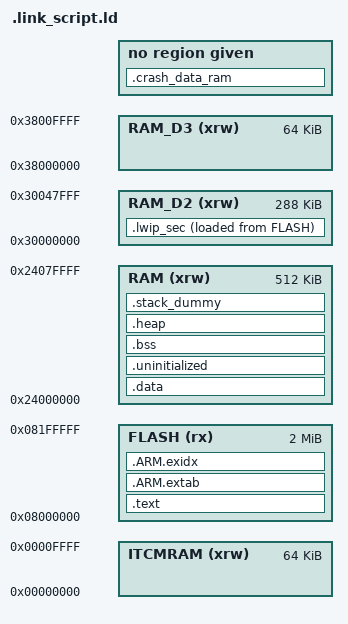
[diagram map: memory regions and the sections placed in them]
#define __STDC__ 1
#define __STDC_VERSION__ 201710L
#define __STDC_UTF_16__ 1
#define __STDC_UTF_32__ 1
#define __STDC_HOSTED__ 1
#define __GNUC__ 11
#define __GNUC_MINOR__ 2
#define __GNUC_PATCHLEVEL__ 1
#define __VERSION__ "11.2.1 20220111"
#define __ATOMIC_RELAXED 0
#define __ATOMIC_SEQ_CST 5
#define __ATOMIC_ACQUIRE 2
#define __ATOMIC_RELEASE 3
#define __ATOMIC_ACQ_REL 4
#define __ATOMIC_CONSUME 1
#define __OPTIMIZE_SIZE__ 1
#define __OPTIMIZE__ 1
#define __FINITE_MATH_ONLY__ 0
#define __SIZEOF_INT__ 4
#define __SIZEOF_LONG__ 4
#define __SIZEOF_LONG_LONG__ 8
#define __SIZEOF_SHORT__ 2
#define __SIZEOF_FLOAT__ 4
#define __SIZEOF_DOUBLE__ 8
#define __SIZEOF_LONG_DOUBLE__ 8
#define __SIZEOF_SIZE_T__ 4
#define __CHAR_BIT__ 8
#define __BIGGEST_ALIGNMENT__ 8
#define __ORDER_LITTLE_ENDIAN__ 1234
#define __ORDER_BIG_ENDIAN__ 4321
#define __ORDER_PDP_ENDIAN__ 3412
#define __BYTE_ORDER__ __ORDER_LITTLE_ENDIAN__
#define __FLOAT_WORD_ORDER__ __ORDER_LITTLE_ENDIAN__
#define __SIZEOF_POINTER__ 4
#define __GNUC_EXECUTION_CHARSET_NAME "UTF-8"
#define __GNUC_WIDE_EXECUTION_CHARSET_NAME "UTF-32LE"
#define __SIZE_TYPE__ unsigned int
#define __PTRDIFF_TYPE__ int
#define __WCHAR_TYPE__ unsigned int
#define __WINT_TYPE__ unsigned int
#define __INTMAX_TYPE__ long long int
#define __UINTMAX_TYPE__ long long unsigned int
#define __CHAR16_TYPE__ short unsigned int
#define __CHAR32_TYPE__ long unsigned int
#define __SIG_ATOMIC_TYPE__ int
#define __INT8_TYPE__ signed char
#define __INT16_TYPE__ short int
#define __INT32_TYPE__ long int
#define __INT64_TYPE__ long long int
#define __UINT8_TYPE__ unsigned char
#define __UINT16_TYPE__ short unsigned int
#define __UINT32_TYPE__ long unsigned int
#define __UINT64_TYPE__ long long unsigned int
#define __INT_LEAST8_TYPE__ signed char
#define __INT_LEAST16_TYPE__ short int
#define __INT_LEAST32_TYPE__ long int
#define __INT_LEAST64_TYPE__ long long int
#define __UINT_LEAST8_TYPE__ unsigned char
#define __UINT_LEAST16_TYPE__ short unsigned int
#define __UINT_LEAST32_TYPE__ long unsigned int
#define __UINT_LEAST64_TYPE__ long long unsigned int
#define __INT_FAST8_TYPE__ int
#define __INT_FAST16_TYPE__ int
#define __INT_FAST32_TYPE__ int
#define __INT_FAST64_TYPE__ long long int
#define __UINT_FAST8_TYPE__ unsigned int
#define __UINT_FAST16_TYPE__ unsigned int
#define __UINT_FAST32_TYPE__ unsigned int
#define __UINT_FAST64_TYPE__ long long unsigned int
#define __INTPTR_TYPE__ int
#define __UINTPTR_TYPE__ unsigned int
#define __GXX_ABI_VERSION 1016
#define __SCHAR_MAX__ 0x7f
#define __SHRT_MAX__ 0x7fff
#define __INT_MAX__ 0x7fffffff
#define __LONG_MAX__ 0x7fffffffL
#define __LONG_LONG_MAX__ 0x7fffffffffffffffLL
#define __WCHAR_MAX__ 0xffffffffU
#define __WCHAR_MIN__ 0U
#define __WINT_MAX__ 0xffffffffU
#define __WINT_MIN__ 0U
#define __PTRDIFF_MAX__ 0x7fffffff
#define __SIZE_MAX__ 0xffffffffU
#define __SCHAR_WIDTH__ 8
#define __SHRT_WIDTH__ 16
#define __INT_WIDTH__ 32
#define __LONG_WIDTH__ 32
#define __LONG_LONG_WIDTH__ 64
#define __WCHAR_WIDTH__ 32
#define __WINT_WIDTH__ 32
#define __PTRDIFF_WIDTH__ 32
#define __SIZE_WIDTH__ 32
#define __INTMAX_MAX__ 0x7fffffffffffffffLL
#define __INTMAX_C(c) c ## LL
#define __UINTMAX_MAX__ 0xffffffffffffffffULL
#define __UINTMAX_C(c) c ## ULL
#define __INTMAX_WIDTH__ 64
#define __SIG_ATOMIC_MAX__ 0x7fffffff
#define __SIG_ATOMIC_MIN__ (-__SIG_ATOMIC_MAX__ - 1)
#define __SIG_ATOMIC_WIDTH__ 32
#define __INT8_MAX__ 0x7f
#define __INT16_MAX__ 0x7fff
#define __INT32_MAX__ 0x7fffffffL
#define __INT64_MAX__ 0x7fffffffffffffffLL
#define __UINT8_MAX__ 0xff
#define __UINT16_MAX__ 0xffff
#define __UINT32_MAX__ 0xffffffffUL
#define __UINT64_MAX__ 0xffffffffffffffffULL
#define __INT_LEAST8_MAX__ 0x7f
#define __INT8_C(c) c
#define __INT_LEAST8_WIDTH__ 8
#define __INT_LEAST16_MAX__ 0x7fff
#define __INT16_C(c) c
#define __INT_LEAST16_WIDTH__ 16
#define __INT_LEAST32_MAX__ 0x7fffffffL
#define __INT32_C(c) c ## L
#define __INT_LEAST32_WIDTH__ 32
#define __INT_LEAST64_MAX__ 0x7fffffffffffffffLL
#define __INT64_C(c) c ## LL
#define __INT_LEAST64_WIDTH__ 64
#define __UINT_LEAST8_MAX__ 0xff
#define __UINT8_C(c) c
#define __UINT_LEAST16_MAX__ 0xffff
#define __UINT16_C(c) c
#define __UINT_LEAST32_MAX__ 0xffffffffUL
#define __UINT32_C(c) c ## UL
#define __UINT_LEAST64_MAX__ 0xffffffffffffffffULL
#define __UINT64_C(c) c ## ULL
#define __INT_FAST8_MAX__ 0x7fffffff
#define __INT_FAST8_WIDTH__ 32
#define __INT_FAST16_MAX__ 0x7fffffff
#define __INT_FAST16_WIDTH__ 32
#define __INT_FAST32_MAX__ 0x7fffffff
#define __INT_FAST32_WIDTH__ 32
#define __INT_FAST64_MAX__ 0x7fffffffffffffffLL
#define __INT_FAST64_WIDTH__ 64
#define __UINT_FAST8_MAX__ 0xffffffffU
#define __UINT_FAST16_MAX__ 0xffffffffU
#define __UINT_FAST32_MAX__ 0xffffffffU
#define __UINT_FAST64_MAX__ 0xffffffffffffffffULL
#define __INTPTR_MAX__ 0x7fffffff
#define __INTPTR_WIDTH__ 32
#define __UINTPTR_MAX__ 0xffffffffU
#define __GCC_IEC_559 2
#define __GCC_IEC_559_COMPLEX 2
#define __FLT_EVAL_METHOD__ 0
#define __FLT_EVAL_METHOD_TS_18661_3__ 0
#define __DEC_EVAL_METHOD__ 2
#define __FLT_RADIX__ 2
#define __FLT_MANT_DIG__ 24
#define __FLT_DIG__ 6
#define __FLT_MIN_EXP__ (-125)
#define __FLT_MIN_10_EXP__ (-37)
#define __FLT_MAX_EXP__ 128
#define __FLT_MAX_10_EXP__ 38
#define __FLT_DECIMAL_DIG__ 9
#define __FLT_MAX__ 3.4028234663852886e+38F
#define __FLT_NORM_MAX__ 3.4028234663852886e+38F
#define __FLT_MIN__ 1.1754943508222875e-38F
#define __FLT_EPSILON__ 1.1920928955078125e-7F
#define __FLT_DENORM_MIN__ 1.4012984643248171e-45F
#define __FLT_HAS_DENORM__ 1
#define __FLT_HAS_INFINITY__ 1
#define __FLT_HAS_QUIET_NAN__ 1
#define __FP_FAST_FMAF 1
#define __FLT_IS_IEC_60559__ 2
#define __DBL_MANT_DIG__ 53
#define __DBL_DIG__ 15
#define __DBL_MIN_EXP__ (-1021)
#define __DBL_MIN_10_EXP__ (-307)
#define __DBL_MAX_EXP__ 1024
#define __DBL_MAX_10_EXP__ 308
#define __DBL_DECIMAL_DIG__ 17
#define __DBL_MAX__ ((double)1.7976931348623157e+308L)
#define __DBL_NORM_MAX__ ((double)1.7976931348623157e+308L)
#define __DBL_MIN__ ((double)2.2250738585072014e-308L)
#define __DBL_EPSILON__ ((double)2.2204460492503131e-16L)
#define __DBL_DENORM_MIN__ ((double)4.9406564584124654e-324L)
#define __DBL_HAS_DENORM__ 1
#define __DBL_HAS_INFINITY__ 1
#define __DBL_HAS_QUIET_NAN__ 1
#define __FP_FAST_FMA 1
#define __DBL_IS_IEC_60559__ 2
#define __LDBL_MANT_DIG__ 53
#define __LDBL_DIG__ 15
#define __LDBL_MIN_EXP__ (-1021)
#define __LDBL_MIN_10_EXP__ (-307)
#define __LDBL_MAX_EXP__ 1024
#define __LDBL_MAX_10_EXP__ 308
#define __DECIMAL_DIG__ 17
#define __LDBL_DECIMAL_DIG__ 17
#define __LDBL_MAX__ 1.7976931348623157e+308L
#define __LDBL_NORM_MAX__ 1.7976931348623157e+308L
#define __LDBL_MIN__ 2.2250738585072014e-308L
#define __LDBL_EPSILON__ 2.2204460492503131e-16L
#define __LDBL_DENORM_MIN__ 4.9406564584124654e-324L
#define __LDBL_HAS_DENORM__ 1
#define __LDBL_HAS_INFINITY__ 1
#define __LDBL_HAS_QUIET_NAN__ 1
#define __FP_FAST_FMAL 1
#define __LDBL_IS_IEC_60559__ 2
#define __FLT32_MANT_DIG__ 24
#define __FLT32_DIG__ 6
#define __FLT32_MIN_EXP__ (-125)
#define __FLT32_MIN_10_EXP__ (-37)
#define __FLT32_MAX_EXP__ 128
#define __FLT32_MAX_10_EXP__ 38
#define __FLT32_DECIMAL_DIG__ 9
#define __FLT32_MAX__ 3.4028234663852886e+38F32
#define __FLT32_NORM_MAX__ 3.4028234663852886e+38F32
#define __FLT32_MIN__ 1.1754943508222875e-38F32
#define __FLT32_EPSILON__ 1.1920928955078125e-7F32
#define __FLT32_DENORM_MIN__ 1.4012984643248171e-45F32
#define __FLT32_HAS_DENORM__ 1
#define __FLT32_HAS_INFINITY__ 1
#define __FLT32_HAS_QUIET_NAN__ 1
#define __FP_FAST_FMAF32 1
#define __FLT32_IS_IEC_60559__ 2
#define __FLT64_MANT_DIG__ 53
#define __FLT64_DIG__ 15
#define __FLT64_MIN_EXP__ (-1021)
#define __FLT64_MIN_10_EXP__ (-307)
#define __FLT64_MAX_EXP__ 1024
#define __FLT64_MAX_10_EXP__ 308
#define __FLT64_DECIMAL_DIG__ 17
#define __FLT64_MAX__ 1.7976931348623157e+308F64
#define __FLT64_NORM_MAX__ 1.7976931348623157e+308F64
#define __FLT64_MIN__ 2.2250738585072014e-308F64
#define __FLT64_EPSILON__ 2.2204460492503131e-16F64
#define __FLT64_DENORM_MIN__ 4.9406564584124654e-324F64
#define __FLT64_HAS_DENORM__ 1
#define __FLT64_HAS_INFINITY__ 1
#define __FLT64_HAS_QUIET_NAN__ 1
#define __FP_FAST_FMAF64 1
#define __FLT64_IS_IEC_60559__ 2
#define __FLT32X_MANT_DIG__ 53
#define __FLT32X_DIG__ 15
#define __FLT32X_MIN_EXP__ (-1021)
#define __FLT32X_MIN_10_EXP__ (-307)
#define __FLT32X_MAX_EXP__ 1024
#define __FLT32X_MAX_10_EXP__ 308
#define __FLT32X_DECIMAL_DIG__ 17
#define __FLT32X_MAX__ 1.7976931348623157e+308F32x
#define __FLT32X_NORM_MAX__ 1.7976931348623157e+308F32x
#define __FLT32X_MIN__ 2.2250738585072014e-308F32x
#define __FLT32X_EPSILON__ 2.2204460492503131e-16F32x
#define __FLT32X_DENORM_MIN__ 4.9406564584124654e-324F32x
#define __FLT32X_HAS_DENORM__ 1
#define __FLT32X_HAS_INFINITY__ 1
#define __FLT32X_HAS_QUIET_NAN__ 1
#define __FP_FAST_FMAF32x 1
#define __FLT32X_IS_IEC_60559__ 2
#define __SFRACT_FBIT__ 7
#define __SFRACT_IBIT__ 0
#define __SFRACT_MIN__ (-0.5HR-0.5HR)
#define __SFRACT_MAX__ 0X7FP-7HR
#define __SFRACT_EPSILON__ 0x1P-7HR
#define __USFRACT_FBIT__ 8
#define __USFRACT_IBIT__ 0
#define __USFRACT_MIN__ 0.0UHR
#define __USFRACT_MAX__ 0XFFP-8UHR
#define __USFRACT_EPSILON__ 0x1P-8UHR
#define __FRACT_FBIT__ 15
#define __FRACT_IBIT__ 0
#define __FRACT_MIN__ (-0.5R-0.5R)
#define __FRACT_MAX__ 0X7FFFP-15R
#define __FRACT_EPSILON__ 0x1P-15R
#define __UFRACT_FBIT__ 16
#define __UFRACT_IBIT__ 0
#define __UFRACT_MIN__ 0.0UR
#define __UFRACT_MAX__ 0XFFFFP-16UR
#define __UFRACT_EPSILON__ 0x1P-16UR
#define __LFRACT_FBIT__ 31
#define __LFRACT_IBIT__ 0
#define __LFRACT_MIN__ (-0.5LR-0.5LR)
#define __LFRACT_MAX__ 0X7FFFFFFFP-31LR
#define __LFRACT_EPSILON__ 0x1P-31LR
#define __ULFRACT_FBIT__ 32
#define __ULFRACT_IBIT__ 0
#define __ULFRACT_MIN__ 0.0ULR
#define __ULFRACT_MAX__ 0XFFFFFFFFP-32ULR
#define __ULFRACT_EPSILON__ 0x1P-32ULR
#define __LLFRACT_FBIT__ 63
#define __LLFRACT_IBIT__ 0
#define __LLFRACT_MIN__ (-0.5LLR-0.5LLR)
#define __LLFRACT_MAX__ 0X7FFFFFFFFFFFFFFFP-63LLR
#define __LLFRACT_EPSILON__ 0x1P-63LLR
#define __ULLFRACT_FBIT__ 64
#define __ULLFRACT_IBIT__ 0
#define __ULLFRACT_MIN__ 0.0ULLR
#define __ULLFRACT_MAX__ 0XFFFFFFFFFFFFFFFFP-64ULLR
#define __ULLFRACT_EPSILON__ 0x1P-64ULLR
#define __SACCUM_FBIT__ 7
#define __SACCUM_IBIT__ 8
#define __SACCUM_MIN__ (-0X1P7HK-0X1P7HK)
#define __SACCUM_MAX__ 0X7FFFP-7HK
#define __SACCUM_EPSILON__ 0x1P-7HK
#define __USACCUM_FBIT__ 8
#define __USACCUM_IBIT__ 8
#define __USACCUM_MIN__ 0.0UHK
#define __USACCUM_MAX__ 0XFFFFP-8UHK
#define __USACCUM_EPSILON__ 0x1P-8UHK
#define __ACCUM_FBIT__ 15
#define __ACCUM_IBIT__ 16
#define __ACCUM_MIN__ (-0X1P15K-0X1P15K)
#define __ACCUM_MAX__ 0X7FFFFFFFP-15K
#define __ACCUM_EPSILON__ 0x1P-15K
#define __UACCUM_FBIT__ 16
#define __UACCUM_IBIT__ 16
#define __UACCUM_MIN__ 0.0UK
#define __UACCUM_MAX__ 0XFFFFFFFFP-16UK
#define __UACCUM_EPSILON__ 0x1P-16UK
#define __LACCUM_FBIT__ 31
#define __LACCUM_IBIT__ 32
#define __LACCUM_MIN__ (-0X1P31LK-0X1P31LK)
#define __LACCUM_MAX__ 0X7FFFFFFFFFFFFFFFP-31LK
#define __LACCUM_EPSILON__ 0x1P-31LK
#define __ULACCUM_FBIT__ 32
#define __ULACCUM_IBIT__ 32
#define __ULACCUM_MIN__ 0.0ULK
#define __ULACCUM_MAX__ 0XFFFFFFFFFFFFFFFFP-32ULK
#define __ULACCUM_EPSILON__ 0x1P-32ULK
#define __LLACCUM_FBIT__ 31
#define __LLACCUM_IBIT__ 32
#define __LLACCUM_MIN__ (-0X1P31LLK-0X1P31LLK)
#define __LLACCUM_MAX__ 0X7FFFFFFFFFFFFFFFP-31LLK
#define __LLACCUM_EPSILON__ 0x1P-31LLK
#define __ULLACCUM_FBIT__ 32
#define __ULLACCUM_IBIT__ 32
#define __ULLACCUM_MIN__ 0.0ULLK
#define __ULLACCUM_MAX__ 0XFFFFFFFFFFFFFFFFP-32ULLK
#define __ULLACCUM_EPSILON__ 0x1P-32ULLK
#define __QQ_FBIT__ 7
#define __QQ_IBIT__ 0
#define __HQ_FBIT__ 15
#define __HQ_IBIT__ 0
#define __SQ_FBIT__ 31
#define __SQ_IBIT__ 0
#define __DQ_FBIT__ 63
#define __DQ_IBIT__ 0
#define __TQ_FBIT__ 127
#define __TQ_IBIT__ 0
#define __UQQ_FBIT__ 8
#define __UQQ_IBIT__ 0
#define __UHQ_FBIT__ 16
#define __UHQ_IBIT__ 0
#define __USQ_FBIT__ 32
#define __USQ_IBIT__ 0
#define __UDQ_FBIT__ 64
#define __UDQ_IBIT__ 0
#define __UTQ_FBIT__ 128
#define __UTQ_IBIT__ 0
#define __HA_FBIT__ 7
#define __HA_IBIT__ 8
#define __SA_FBIT__ 15
#define __SA_IBIT__ 16
#define __DA_FBIT__ 31
#define __DA_IBIT__ 32
#define __TA_FBIT__ 63
#define __TA_IBIT__ 64
#define __UHA_FBIT__ 8
#define __UHA_IBIT__ 8
#define __USA_FBIT__ 16
#define __USA_IBIT__ 16
#define __UDA_FBIT__ 32
#define __UDA_IBIT__ 32
#define __UTA_FBIT__ 64
#define __UTA_IBIT__ 64
#define __REGISTER_PREFIX__ 
#define __USER_LABEL_PREFIX__ 
#define __GNUC_STDC_INLINE__ 1
#define __CHAR_UNSIGNED__ 1
#define __GCC_HAVE_SYNC_COMPARE_AND_SWAP_1 1
#define __GCC_HAVE_SYNC_COMPARE_AND_SWAP_2 1
#define __GCC_HAVE_SYNC_COMPARE_AND_SWAP_4 1
#define __GCC_ATOMIC_BOOL_LOCK_FREE 2
#define __GCC_ATOMIC_CHAR_LOCK_FREE 2
#define __GCC_ATOMIC_CHAR16_T_LOCK_FREE 2
#define __GCC_ATOMIC_CHAR32_T_LOCK_FREE 2
#define __GCC_ATOMIC_WCHAR_T_LOCK_FREE 2
#define __GCC_ATOMIC_SHORT_LOCK_FREE 2
#define __GCC_ATOMIC_INT_LOCK_FREE 2
#define __GCC_ATOMIC_LONG_LOCK_FREE 2
#define __GCC_ATOMIC_LLONG_LOCK_FREE 1
#define __GCC_ATOMIC_TEST_AND_SET_TRUEVAL 1
#define __GCC_ATOMIC_POINTER_LOCK_FREE 2
#define __HAVE_SPECULATION_SAFE_VALUE 1
#define __GCC_HAVE_DWARF2_CFI_ASM 1
#define __PRAGMA_REDEFINE_EXTNAME 1
#define __SIZEOF_WCHAR_T__ 4
#define __SIZEOF_WINT_T__ 4
#define __SIZEOF_PTRDIFF_T__ 4
#define __ARM_FEATURE_DSP 1
#define __ARM_FEATURE_QBIT 1
#define __ARM_FEATURE_SAT 1
#undef __ARM_FEATURE_CRYPTO
#define __ARM_FEATURE_UNALIGNED 1
#undef __ARM_FEATURE_QRDMX
#undef __ARM_FEATURE_CRC32
#undef __ARM_FEATURE_DOTPROD
#undef __ARM_FEATURE_COMPLEX
#define __ARM_32BIT_STATE 1
#undef __ARM_FEATURE_MVE
#undef __ARM_FEATURE_CMSE
#undef __ARM_FEATURE_LDREX
#define __ARM_FEATURE_LDREX 7
#define __ARM_FEATURE_CLZ 1
#undef __ARM_FEATURE_NUMERIC_MAXMIN
#define __ARM_FEATURE_SIMD32 1
#define __ARM_SIZEOF_MINIMAL_ENUM 1
#define __ARM_SIZEOF_WCHAR_T 4
#undef __ARM_ARCH_PROFILE
#define __ARM_ARCH_PROFILE 77
#define __arm__ 1
#undef __ARM_ARCH
#define __ARM_ARCH 7
#define __APCS_32__ 1
#define __GCC_ASM_FLAG_OUTPUTS__ 1
#define __thumb__ 1
#define __thumb2__ 1
#define __THUMBEL__ 1
#undef __ARM_ARCH_ISA_THUMB
#define __ARM_ARCH_ISA_THUMB 2
#define __ARMEL__ 1
#define __VFP_FP__ 1
#undef __ARM_FP
#define __ARM_FP 14
#undef __ARM_FP16_FORMAT_IEEE
#undef __ARM_FP16_FORMAT_ALTERNATIVE
#undef __ARM_FP16_ARGS
#undef __ARM_FEATURE_FP16_SCALAR_ARITHMETIC
#undef __ARM_FEATURE_FP16_VECTOR_ARITHMETIC
#undef __ARM_FEATURE_FP16_FML
#define __ARM_FEATURE_FMA 1
#undef __ARM_NEON__
#undef __ARM_NEON
#undef __ARM_NEON_FP
#define __THUMB_INTERWORK__ 1
#define __ARM_ARCH_7EM__ 1
#define __ARM_PCS 1
#define __ARM_EABI__ 1
#undef __FDPIC__
#define __ARM_ARCH_EXT_IDIV__ 1
#define __ARM_FEATURE_IDIV 1
#define __ARM_ASM_SYNTAX_UNIFIED__ 1
#undef __ARM_FEATURE_COPROC
#define __ARM_FEATURE_COPROC 15
#undef __ARM_FEATURE_CDE
#undef __ARM_FEATURE_CDE_COPROC
#undef __ARM_FEATURE_MATMUL_INT8
#undef __ARM_FEATURE_BF16_SCALAR_ARITHMETIC
#undef __ARM_FEATURE_BF16_VECTOR_ARITHMETIC
#undef __ARM_BF16_FORMAT_ALTERNATIVE
#define __GXX_TYPEINFO_EQUALITY_INLINE 0
#define __ELF__ 1
#define __USES_INITFINI__ 1
#define MBED_TRAP_ERRORS_ENABLED 1
#define BOOST_NO_PLATFORM_CONFIG 1
#define RT_ARM_MBED 1
#define RT_DEVS 1
#define MBED_MINIMAL_PRINTF 1
#define MBED_ROM_START 0x8000000
#define MBED_ROM_SIZE 0x200000
#define MBED_RAM_START 0x20000000
#define MBED_RAM_SIZE 0x20000
#define MBED_RAM1_START 0x24000000
#define MBED_RAM1_SIZE 0x80000
#define MBED_BOOT_STACK_SIZE 1024
#define XIP_ENABLE 0
#define TARGET_NUCLEO_H743ZI2 1
#define __CMSIS_RTOS 1
#define COMPONENT_FLASHIAP 1
#define MBED_TICKLESS 1
#define DEVICE_CAN 1
#define TARGET_LIKE_CORTEX_M7 1
#define DEVICE_PORTIN 1
#define TOOLCHAIN_GCC_ARM 1
#define __FPU_PRESENT 1
#define USE_FULL_LL_DRIVER 1
#define DEVICE_PORTOUT 1
#define TARGET_NAME NUCLEO_H743ZI2
#define DEVICE_I2C_ASYNCH 1
#define TARGET_STM32H743xI 1
#define TARGET_RTOS_M4_M7 1
#define DEVICE_SPI_ASYNCH 1
#define TARGET_FF_ARDUINO_UNO 1
#define __MBED_CMSIS_RTOS_CM 1
#define DEVICE_TRNG 1
#define MBED_BUILD_TIMESTAMP 1658340624.951455
#define DEVICE_RESET_REASON 1
#define DEVICE_SLEEP 1
#define DEVICE_PWMOUT 1
#define DEVICE_LPTICKER 1
#define TARGET_CORTEX 1
#define DEVICE_SERIAL 1
#define DEVICE_FLASH 1
#define STM32H743xx 1
#define TARGET_MCU_STM32H7 1
#define DEVICE_USBDEVICE 1
#define TARGET_LIKE_MBED 1
#define DEVICE_ANALOGOUT 1
#define TARGET_MCU_STM32 1
#define __MBED__ 1
#define DEVICE_INTERRUPTIN 1
#define DEVICE_MPU 1
#define DEVICE_SPISLAVE 1
#define TARGET_CORTEX_M 1
#define TARGET_M7 1
#define TOOLCHAIN_GCC 1
#define USE_HAL_DRIVER 1
#define DEVICE_EMAC 1
#define DEVICE_SERIAL_FC 1
#define TARGET_MCU_STM32H743xI 1
#define DEVICE_PORTINOUT 1
#define TARGET_STM 1
#define DEVICE_I2CSLAVE 1
#define DEVICE_CRC 1
#define DEVICE_USTICKER 1
#define ARM_MATH_CM7 1
#define EXTRA_IDLE_STACK_REQUIRED 1
#define DEVICE_WATCHDOG 1
#define DEVICE_RTC 1
#define DEVICE_STDIO_MESSAGES 1
#define __CORTEX_M7 1
#define DEVICE_ANALOGIN 1
#define TARGET_STM32H7 1
#define TARGET_RELEASE 1
#define TRANSACTION_QUEUE_SIZE_SPI 2
#define DEVICE_SPI 1
#define DEVICE_I2C 1
#define __MBED_CONFIG_DATA__ 
#define CLOCK_SOURCE USE_PLL_HSE_EXTC|USE_PLL_HSI
#define HSE_VALUE 8000000
#define LPTICKER_DELAY_TICKS 0
#define MBED_CONF_ALT1250_PPP_BAUDRATE 115200
#define MBED_CONF_ALT1250_PPP_PROVIDE_DEFAULT 0
#define MBED_CONF_ATMEL_RF_ASSUME_SPACED_SPI 1
#define MBED_CONF_ATMEL_RF_FULL_SPI_SPEED 7500000
#define MBED_CONF_ATMEL_RF_FULL_SPI_SPEED_BYTE_SPACING 250
#define MBED_CONF_ATMEL_RF_IRQ_THREAD_STACK_SIZE 1024
#define MBED_CONF_ATMEL_RF_LOW_SPI_SPEED 3750000
#define MBED_CONF_ATMEL_RF_PROVIDE_DEFAULT 0
#define MBED_CONF_ATMEL_RF_USE_SPI_SPACING_API 0
#define MBED_CONF_CELLULAR_AT_HANDLER_BUFFER_SIZE 32
#define MBED_CONF_CELLULAR_CONTROL_PLANE_OPT 0
#define MBED_CONF_CELLULAR_DEBUG_AT 0
#define MBED_CONF_CELLULAR_MAX_CP_DATA_RECV_LEN 1358
#define MBED_CONF_CELLULAR_PRESENT 1
#define MBED_CONF_CELLULAR_RANDOM_MAX_START_DELAY 0
#define MBED_CONF_CELLULAR_USE_APN_LOOKUP 0
#define MBED_CONF_CELLULAR_USE_SMS 0
#define MBED_CONF_DRIVERS_OSPI_CSN OSPI_FLASH1_CSN
#define MBED_CONF_DRIVERS_OSPI_DQS OSPI_FLASH1_DQS
#define MBED_CONF_DRIVERS_OSPI_IO0 OSPI_FLASH1_IO0
#define MBED_CONF_DRIVERS_OSPI_IO1 OSPI_FLASH1_IO1
#define MBED_CONF_DRIVERS_OSPI_IO2 OSPI_FLASH1_IO2
#define MBED_CONF_DRIVERS_OSPI_IO3 OSPI_FLASH1_IO3
#define MBED_CONF_DRIVERS_OSPI_IO4 OSPI_FLASH1_IO4
#define MBED_CONF_DRIVERS_OSPI_IO5 OSPI_FLASH1_IO5
#define MBED_CONF_DRIVERS_OSPI_IO6 OSPI_FLASH1_IO6
#define MBED_CONF_DRIVERS_OSPI_IO7 OSPI_FLASH1_IO7
#define MBED_CONF_DRIVERS_OSPI_SCK OSPI_FLASH1_SCK
#define MBED_CONF_DRIVERS_QSPI_CSN QSPI_FLASH1_CSN
#define MBED_CONF_DRIVERS_QSPI_IO0 QSPI_FLASH1_IO0
#define MBED_CONF_DRIVERS_QSPI_IO1 QSPI_FLASH1_IO1
#define MBED_CONF_DRIVERS_QSPI_IO2 QSPI_FLASH1_IO2
#define MBED_CONF_DRIVERS_QSPI_IO3 QSPI_FLASH1_IO3
#define MBED_CONF_DRIVERS_QSPI_SCK QSPI_FLASH1_SCK
#define MBED_CONF_DRIVERS_UART_SERIAL_RXBUF_SIZE 256
#define MBED_CONF_DRIVERS_UART_SERIAL_TXBUF_SIZE 256
#define MBED_CONF_ESP8266_BUILT_IN_DNS 0
#define MBED_CONF_ESP8266_DEBUG 0
#define MBED_CONF_ESP8266_POWER_OFF_TIME_MS 3
#define MBED_CONF_ESP8266_POWER_ON_POLARITY 0
#define MBED_CONF_ESP8266_POWER_ON_TIME_MS 3
#define MBED_CONF_ESP8266_PROVIDE_DEFAULT 0
#define MBED_CONF_ESP8266_SERIAL_BAUDRATE 115200
#define MBED_CONF_ESP8266_SNTP_ENABLE 0
#define MBED_CONF_ESP8266_SNTP_SERVER0 ""
#define MBED_CONF_ESP8266_SNTP_SERVER1 ""
#define MBED_CONF_ESP8266_SNTP_SERVER2 ""
#define MBED_CONF_ESP8266_SNTP_TIMEZONE 0
#define MBED_CONF_ESP8266_SOCKET_BUFSIZE 8192
#define MBED_CONF_EVENTS_PRESENT 1
#define MBED_CONF_EVENTS_SHARED_DISPATCH_FROM_APPLICATION 0
#define MBED_CONF_EVENTS_SHARED_EVENTSIZE 768
#define MBED_CONF_EVENTS_SHARED_HIGHPRIO_EVENTSIZE 256
#define MBED_CONF_EVENTS_SHARED_HIGHPRIO_STACKSIZE 1024
#define MBED_CONF_EVENTS_SHARED_STACKSIZE 2048
#define MBED_CONF_EVENTS_USE_LOWPOWER_TIMER_TICKER 0
#define MBED_CONF_FAT_CHAN_FFS_DBG 0
#define MBED_CONF_FAT_CHAN_FF_CODE_PAGE 437
#define MBED_CONF_FAT_CHAN_FF_FS_EXFAT 0
#define MBED_CONF_FAT_CHAN_FF_FS_HEAPBUF 1
#define MBED_CONF_FAT_CHAN_FF_FS_LOCK 0
#define MBED_CONF_FAT_CHAN_FF_FS_MINIMIZE 0
#define MBED_CONF_FAT_CHAN_FF_FS_NOFSINFO 0
#define MBED_CONF_FAT_CHAN_FF_FS_NORTC 0
#define MBED_CONF_FAT_CHAN_FF_FS_READONLY 0
#define MBED_CONF_FAT_CHAN_FF_FS_REENTRANT 0
#define MBED_CONF_FAT_CHAN_FF_FS_RPATH 1
#define MBED_CONF_FAT_CHAN_FF_FS_TIMEOUT 1000
#define MBED_CONF_FAT_CHAN_FF_FS_TINY 1
#define MBED_CONF_FAT_CHAN_FF_LFN_BUF 255
#define MBED_CONF_FAT_CHAN_FF_LFN_UNICODE 0
#define MBED_CONF_FAT_CHAN_FF_MAX_LFN 255
#define MBED_CONF_FAT_CHAN_FF_MAX_SS 4096
#define MBED_CONF_FAT_CHAN_FF_MIN_SS 512
#define MBED_CONF_FAT_CHAN_FF_MULTI_PARTITION 0
#define MBED_CONF_FAT_CHAN_FF_NORTC_MDAY 1
#define MBED_CONF_FAT_CHAN_FF_NORTC_MON 1
#define MBED_CONF_FAT_CHAN_FF_NORTC_YEAR 2017
#define MBED_CONF_FAT_CHAN_FF_PRINT_FLOAT 0
#define MBED_CONF_FAT_CHAN_FF_PRINT_LLI 0
#define MBED_CONF_FAT_CHAN_FF_SFN_BUF 12
#define MBED_CONF_FAT_CHAN_FF_STRF_ENCODE 3
#define MBED_CONF_FAT_CHAN_FF_STR_VOLUME_ID 0
#define MBED_CONF_FAT_CHAN_FF_SYNC_T HANDLE
#define MBED_CONF_FAT_CHAN_FF_USE_CHMOD 0
#define MBED_CONF_FAT_CHAN_FF_USE_EXPAND 0
#define MBED_CONF_FAT_CHAN_FF_USE_FASTSEEK 0
#define MBED_CONF_FAT_CHAN_FF_USE_FIND 0
#define MBED_CONF_FAT_CHAN_FF_USE_FORWARD 0
#define MBED_CONF_FAT_CHAN_FF_USE_LABEL 0
#define MBED_CONF_FAT_CHAN_FF_USE_LFN 3
#define MBED_CONF_FAT_CHAN_FF_USE_MKFS 1
#define MBED_CONF_FAT_CHAN_FF_USE_STRFUNC 0
#define MBED_CONF_FAT_CHAN_FF_USE_TRIM 1
#define MBED_CONF_FAT_CHAN_FF_VOLUMES 4
#define MBED_CONF_FAT_CHAN_FF_VOLUME_STRS "RAM","NAND","CF","SD","SD2","USB","USB2","USB3"
#define MBED_CONF_FAT_CHAN_FLUSH_ON_NEW_CLUSTER 0
#define MBED_CONF_FAT_CHAN_FLUSH_ON_NEW_SECTOR 1
#define MBED_CONF_FILESYSTEM_PRESENT 1
#define MBED_CONF_FLASHIAP_BLOCK_DEVICE_BASE_ADDRESS 0xFFFFFFFF
#define MBED_CONF_FLASHIAP_BLOCK_DEVICE_SIZE 0
#define MBED_CONF_GEMALTO_CINTERION_BAUDRATE 115200
#define MBED_CONF_GEMALTO_CINTERION_PROVIDE_DEFAULT 0
#define MBED_CONF_GENERIC_AT3GPP_BAUDRATE 115200
#define MBED_CONF_GENERIC_AT3GPP_PROVIDE_DEFAULT 0
#define MBED_CONF_LORA_ADR_ON 1
#define MBED_CONF_LORA_APPLICATION_EUI {0x00, 0x00, 0x00, 0x00, 0x00, 0x00, 0x00, 0x00}
#define MBED_CONF_LORA_APPLICATION_KEY {0x00, 0x00, 0x00, 0x00, 0x00, 0x00, 0x00, 0x00, 0x00, 0x00, 0x00, 0x00, 0x00, 0x00, 0x00, 0x00}
#define MBED_CONF_LORA_APPSKEY {0x00, 0x00, 0x00, 0x00, 0x00, 0x00, 0x00, 0x00, 0x00, 0x00, 0x00, 0x00, 0x00, 0x00, 0x00, 0x00}
#define MBED_CONF_LORA_APP_PORT 15
#define MBED_CONF_LORA_AUTOMATIC_UPLINK_MESSAGE 1
#define MBED_CONF_LORA_DEVICE_ADDRESS 0x00000000
#define MBED_CONF_LORA_DEVICE_EUI {0x00, 0x00, 0x00, 0x00, 0x00, 0x00, 0x00, 0x00}
#define MBED_CONF_LORA_DOWNLINK_PREAMBLE_LENGTH 5
#define MBED_CONF_LORA_DUTY_CYCLE_ON 1
#define MBED_CONF_LORA_DUTY_CYCLE_ON_JOIN 1
#define MBED_CONF_LORA_FSB_MASK {0xFFFF, 0xFFFF, 0xFFFF, 0xFFFF, 0x00FF}
#define MBED_CONF_LORA_FSB_MASK_CHINA {0xFFFF, 0xFFFF, 0xFFFF, 0xFFFF, 0xFFFF, 0xFFFF}
#define MBED_CONF_LORA_LBT_ON 0
#define MBED_CONF_LORA_MAX_SYS_RX_ERROR 5
#define MBED_CONF_LORA_NB_TRIALS 12
#define MBED_CONF_LORA_NWKSKEY {0x00, 0x00, 0x00, 0x00, 0x00, 0x00, 0x00, 0x00, 0x00, 0x00, 0x00, 0x00, 0x00, 0x00, 0x00, 0x00}
#define MBED_CONF_LORA_OVER_THE_AIR_ACTIVATION 1
#define MBED_CONF_LORA_PHY EU868
#define MBED_CONF_LORA_PUBLIC_NETWORK 1
#define MBED_CONF_LORA_TX_MAX_SIZE 64
#define MBED_CONF_LORA_UPLINK_PREAMBLE_LENGTH 8
#define MBED_CONF_LORA_WAKEUP_TIME 5
#define MBED_CONF_LWIP_ADDR_TIMEOUT 5
#define MBED_CONF_LWIP_ADDR_TIMEOUT_MODE 1
#define MBED_CONF_LWIP_DEBUG_ENABLED 0
#define MBED_CONF_LWIP_DEFAULT_THREAD_STACKSIZE 512
#define MBED_CONF_LWIP_DHCP_TIMEOUT 60
#define MBED_CONF_LWIP_ENABLE_PPP_TRACE 0
#define MBED_CONF_LWIP_ETHERNET_ENABLED 1
#define MBED_CONF_LWIP_IPV4_ENABLED 1
#define MBED_CONF_LWIP_IPV6_ENABLED 0
#define MBED_CONF_LWIP_IP_VER_PREF 4
#define MBED_CONF_LWIP_L3IP_ENABLED 0
#define MBED_CONF_LWIP_MBOX_SIZE 8
#define MBED_CONF_LWIP_MEMP_NUM_TCPIP_MSG_INPKT 8
#define MBED_CONF_LWIP_MEMP_NUM_TCP_SEG 16
#define MBED_CONF_LWIP_MEM_SIZE 2310
#define MBED_CONF_LWIP_ND6_QUEUEING 0
#define MBED_CONF_LWIP_ND6_RDNSS_MAX_DNS_SERVERS 0
#define MBED_CONF_LWIP_NETBUF_RECVINFO_ENABLED 0
#define MBED_CONF_LWIP_NUM_NETBUF 8
#define MBED_CONF_LWIP_NUM_PBUF 8
#define MBED_CONF_LWIP_PBUF_POOL_SIZE 5
#define MBED_CONF_LWIP_PPP_ENABLED 0
#define MBED_CONF_LWIP_PPP_IPV4_ENABLED 0
#define MBED_CONF_LWIP_PPP_IPV6_ENABLED 0
#define MBED_CONF_LWIP_PPP_THREAD_STACKSIZE 768
#define MBED_CONF_LWIP_PRESENT 1
#define MBED_CONF_LWIP_RAW_SOCKET_ENABLED 0
#define MBED_CONF_LWIP_SOCKET_MAX 4
#define MBED_CONF_LWIP_TCPIP_THREAD_PRIORITY osPriorityNormal
#define MBED_CONF_LWIP_TCPIP_THREAD_STACKSIZE 1200
#define MBED_CONF_LWIP_TCP_CLOSE_TIMEOUT 1000
#define MBED_CONF_LWIP_TCP_ENABLED 1
#define MBED_CONF_LWIP_TCP_MAXRTX 6
#define MBED_CONF_LWIP_TCP_MSS 536
#define MBED_CONF_LWIP_TCP_SERVER_MAX 4
#define MBED_CONF_LWIP_TCP_SND_BUF (2 * TCP_MSS)
#define MBED_CONF_LWIP_TCP_SOCKET_MAX 4
#define MBED_CONF_LWIP_TCP_SYNMAXRTX 6
#define MBED_CONF_LWIP_TCP_WND (4 * TCP_MSS)
#define MBED_CONF_LWIP_UDP_SOCKET_MAX 4
#define MBED_CONF_LWIP_USE_MBED_TRACE 0
#define MBED_CONF_MBED_MESH_API_6LOWPAN_ND_CHANNEL 0
#define MBED_CONF_MBED_MESH_API_6LOWPAN_ND_CHANNEL_MASK 0x7fff800
#define MBED_CONF_MBED_MESH_API_6LOWPAN_ND_CHANNEL_PAGE 0
#define MBED_CONF_MBED_MESH_API_6LOWPAN_ND_DEVICE_TYPE NET_6LOWPAN_ROUTER
#define MBED_CONF_MBED_MESH_API_6LOWPAN_ND_PANID_FILTER 0xffff
#define MBED_CONF_MBED_MESH_API_6LOWPAN_ND_PSK_KEY {0xa0, 0xa1, 0xa2, 0xa3, 0xa4, 0xa5, 0xa6, 0xa7, 0xa8, 0xa9, 0xaa, 0xab, 0xac, 0xad, 0xae, 0xaf}
#define MBED_CONF_MBED_MESH_API_6LOWPAN_ND_PSK_KEY_ID 1
#define MBED_CONF_MBED_MESH_API_6LOWPAN_ND_SECURITY_MODE NONE
#define MBED_CONF_MBED_MESH_API_6LOWPAN_ND_SEC_LEVEL 5
#define MBED_CONF_MBED_MESH_API_HEAP_SIZE 32500
#define MBED_CONF_MBED_MESH_API_HEAP_STAT_INFO NULL
#define MBED_CONF_MBED_MESH_API_MAC_NEIGH_TABLE_SIZE 32
#define MBED_CONF_MBED_MESH_API_RADIUS_RETRY_COUNT 3
#define MBED_CONF_MBED_MESH_API_RADIUS_RETRY_IMAX 30
#define MBED_CONF_MBED_MESH_API_RADIUS_RETRY_IMIN 20
#define MBED_CONF_MBED_MESH_API_SYSTEM_TIME_UPDATE_FROM_NANOSTACK 1
#define MBED_CONF_MBED_MESH_API_THREAD_CONFIG_CHANNEL 22
#define MBED_CONF_MBED_MESH_API_THREAD_CONFIG_CHANNEL_MASK 0x7fff800
#define MBED_CONF_MBED_MESH_API_THREAD_CONFIG_CHANNEL_PAGE 0
#define MBED_CONF_MBED_MESH_API_THREAD_CONFIG_COMMISSIONING_DATASET_TIMESTAMP 0x10000
#define MBED_CONF_MBED_MESH_API_THREAD_CONFIG_EXTENDED_PANID {0xf1, 0xb5, 0xa1, 0xb2,0xc4, 0xd5, 0xa1, 0xbd }
#define MBED_CONF_MBED_MESH_API_THREAD_CONFIG_ML_PREFIX {0xfd, 0x0, 0x0d, 0xb8, 0x0, 0x0, 0x0, 0x0}
#define MBED_CONF_MBED_MESH_API_THREAD_CONFIG_NETWORK_NAME "Thread Network"
#define MBED_CONF_MBED_MESH_API_THREAD_CONFIG_PANID 0x0700
#define MBED_CONF_MBED_MESH_API_THREAD_CONFIG_PSKC {0xc8, 0xa6, 0x2e, 0xae, 0xf3, 0x68, 0xf3, 0x46, 0xa9, 0x9e, 0x57, 0x85, 0x98, 0x9d, 0x1c, 0xd0}
#define MBED_CONF_MBED_MESH_API_THREAD_DEVICE_TYPE MESH_DEVICE_TYPE_THREAD_ROUTER
#define MBED_CONF_MBED_MESH_API_THREAD_MASTER_KEY {0x10, 0x11, 0x22, 0x33, 0x44, 0x55, 0x66, 0x77, 0x88, 0x99, 0xaa, 0xbb, 0xcc, 0xdd, 0xee, 0xff}
#define MBED_CONF_MBED_MESH_API_THREAD_PSKD "ABCDEFGH"
#define MBED_CONF_MBED_MESH_API_THREAD_SECURITY_POLICY 255
#define MBED_CONF_MBED_MESH_API_THREAD_USE_STATIC_LINK_CONFIG 1
#define MBED_CONF_MBED_MESH_API_USE_MALLOC_FOR_HEAP 0
#define MBED_CONF_MBED_MESH_API_WISUN_BC_CHANNEL_FUNCTION 255
#define MBED_CONF_MBED_MESH_API_WISUN_BC_DWELL_INTERVAL 0
#define MBED_CONF_MBED_MESH_API_WISUN_BC_FIXED_CHANNEL 65535
#define MBED_CONF_MBED_MESH_API_WISUN_BC_INTERVAL 0
#define MBED_CONF_MBED_MESH_API_WISUN_CHANNEL_PLAN_ID 255
#define MBED_CONF_MBED_MESH_API_WISUN_DEVICE_TYPE MESH_DEVICE_TYPE_WISUN_ROUTER
#define MBED_CONF_MBED_MESH_API_WISUN_NETWORK_NAME "Wi-SUN Network"
#define MBED_CONF_MBED_MESH_API_WISUN_OPERATING_CLASS 255
#define MBED_CONF_MBED_MESH_API_WISUN_OPERATING_MODE 255
#define MBED_CONF_MBED_MESH_API_WISUN_PHY_MODE_ID 255
#define MBED_CONF_MBED_MESH_API_WISUN_REGULATORY_DOMAIN 3
#define MBED_CONF_MBED_MESH_API_WISUN_UC_CHANNEL_FUNCTION 255
#define MBED_CONF_MBED_MESH_API_WISUN_UC_DWELL_INTERVAL 255
#define MBED_CONF_MBED_MESH_API_WISUN_UC_FIXED_CHANNEL 65535
#define MBED_CONF_MCR20A_PROVIDE_DEFAULT 0
#define MBED_CONF_NANOSTACK_CONFIGURATION nanostack_full
#define MBED_CONF_NANOSTACK_HAL_CRITICAL_SECTION_USABLE_FROM_INTERRUPT 0
#define MBED_CONF_NANOSTACK_HAL_EVENT_LOOP_DISPATCH_FROM_APPLICATION 0
#define MBED_CONF_NANOSTACK_HAL_EVENT_LOOP_THREAD_STACK_SIZE 6144
#define MBED_CONF_NANOSTACK_HAL_EVENT_LOOP_USE_MBED_EVENTS 0
#define MBED_CONF_NANOSTACK_HAL_KVSTORE_PATH "/kv/"
#define MBED_CONF_NANOSTACK_HAL_USE_KVSTORE 0
#define MBED_CONF_NANOSTACK_LIBSERVICE_NSDYNMEM_TRACKER_ENABLED 0
#define MBED_CONF_NANOSTACK_LIBSERVICE_PRESENT 1
#define MBED_CONF_NSAPI_ADD_EVENT_LISTENER_RETURN_CHANGE 0
#define MBED_CONF_NSAPI_DEFAULT_MESH_TYPE THREAD
#define MBED_CONF_NSAPI_DEFAULT_STACK LWIP
#define MBED_CONF_NSAPI_DEFAULT_WIFI_SECURITY NONE
#define MBED_CONF_NSAPI_DNS_ADDRESSES_LIMIT 10
#define MBED_CONF_NSAPI_DNS_CACHE_SIZE 3
#define MBED_CONF_NSAPI_DNS_RESPONSE_WAIT_TIME 10000
#define MBED_CONF_NSAPI_DNS_RETRIES 1
#define MBED_CONF_NSAPI_DNS_TOTAL_ATTEMPTS 10
#define MBED_CONF_NSAPI_PRESENT 1
#define MBED_CONF_NSAPI_SOCKET_STATS_ENABLED 0
#define MBED_CONF_NSAPI_SOCKET_STATS_MAX_COUNT 10
#define MBED_CONF_PLATFORM_CALLBACK_COMPARABLE 1
#define MBED_CONF_PLATFORM_CALLBACK_NONTRIVIAL 0
#define MBED_CONF_PLATFORM_CRASH_CAPTURE_ENABLED 0
#define MBED_CONF_PLATFORM_CTHUNK_COUNT_MAX 8
#define MBED_CONF_PLATFORM_DEEPSLEEP_STATS_VERBOSE 0
#define MBED_CONF_PLATFORM_DEFAULT_SERIAL_BAUD_RATE 9600
#define MBED_CONF_PLATFORM_ERROR_ALL_THREADS_INFO 0
#define MBED_CONF_PLATFORM_ERROR_FILENAME_CAPTURE_ENABLED 0
#define MBED_CONF_PLATFORM_ERROR_HIST_ENABLED 0
#define MBED_CONF_PLATFORM_ERROR_HIST_SIZE 4
#define MBED_CONF_PLATFORM_ERROR_REBOOT_MAX 1
#define MBED_CONF_PLATFORM_FATAL_ERROR_AUTO_REBOOT_ENABLED 0
#define MBED_CONF_PLATFORM_MAX_ERROR_FILENAME_LEN 16
#define MBED_CONF_PLATFORM_MINIMAL_PRINTF_ENABLE_64_BIT 1
#define MBED_CONF_PLATFORM_MINIMAL_PRINTF_ENABLE_FLOATING_POINT 0
#define MBED_CONF_PLATFORM_MINIMAL_PRINTF_SET_FLOATING_POINT_MAX_DECIMALS 6
#define MBED_CONF_PLATFORM_POLL_USE_LOWPOWER_TIMER 0
#define MBED_CONF_PLATFORM_STDIO_BAUD_RATE 9600
#define MBED_CONF_PLATFORM_STDIO_BUFFERED_SERIAL 0
#define MBED_CONF_PLATFORM_STDIO_CONVERT_NEWLINES 1
#define MBED_CONF_PLATFORM_STDIO_CONVERT_TTY_NEWLINES 1
#define MBED_CONF_PLATFORM_STDIO_FLUSH_AT_EXIT 1
#define MBED_CONF_PLATFORM_STDIO_MINIMAL_CONSOLE_ONLY 0
#define MBED_CONF_PLATFORM_USE_MPU 1
#define MBED_CONF_PPP_ENABLED 0
#define MBED_CONF_PPP_ENABLE_TRACE 0
#define MBED_CONF_PPP_IPV4_ENABLED 1
#define MBED_CONF_PPP_IPV6_ENABLED 0
#define MBED_CONF_PPP_MBED_EVENT_QUEUE 0
#define MBED_CONF_PPP_THREAD_STACKSIZE 816
#define MBED_CONF_QUECTEL_BC95_BAUDRATE 9600
#define MBED_CONF_QUECTEL_BC95_PROVIDE_DEFAULT 0
#define MBED_CONF_QUECTEL_BG96_BAUDRATE 115200
#define MBED_CONF_QUECTEL_BG96_PROVIDE_DEFAULT 0
#define MBED_CONF_QUECTEL_EC2X_BAUDRATE 115200
#define MBED_CONF_QUECTEL_EC2X_PROVIDE_DEFAULT 0
#define MBED_CONF_QUECTEL_EC2X_START_TIMEOUT 15000
#define MBED_CONF_QUECTEL_M26_BAUDRATE 115200
#define MBED_CONF_QUECTEL_M26_PROVIDE_DEFAULT 0
#define MBED_CONF_QUECTEL_UG96_BAUDRATE 115200
#define MBED_CONF_QUECTEL_UG96_PROVIDE_DEFAULT 0
#define MBED_CONF_RM1000_AT_BAUDRATE 230400
#define MBED_CONF_RM1000_AT_PROVIDE_DEFAULT 0
#define MBED_CONF_RTOS_API_PRESENT 1
#define MBED_CONF_RTOS_ENABLE_ALL_RTX_EVENTS 0
#define MBED_CONF_RTOS_EVFLAGS_NUM 0
#define MBED_CONF_RTOS_IDLE_THREAD_STACK_SIZE 512
#define MBED_CONF_RTOS_IDLE_THREAD_STACK_SIZE_DEBUG_EXTRA 128
#define MBED_CONF_RTOS_IDLE_THREAD_STACK_SIZE_TICKLESS_EXTRA 256
#define MBED_CONF_RTOS_MAIN_THREAD_STACK_SIZE 4096
#define MBED_CONF_RTOS_MSGQUEUE_DATA_SIZE 0
#define MBED_CONF_RTOS_MSGQUEUE_NUM 0
#define MBED_CONF_RTOS_MUTEX_NUM 0
#define MBED_CONF_RTOS_PRESENT 1
#define MBED_CONF_RTOS_SEMAPHORE_NUM 0
#define MBED_CONF_RTOS_THREAD_NUM 0
#define MBED_CONF_RTOS_THREAD_STACK_SIZE 4096
#define MBED_CONF_RTOS_THREAD_USER_STACK_SIZE 0
#define MBED_CONF_RTOS_TIMER_NUM 0
#define MBED_CONF_RTOS_TIMER_THREAD_STACK_SIZE 768
#define MBED_CONF_S2LP_PROVIDE_DEFAULT 0
#define MBED_CONF_SARA4_PPP_BAUDRATE 115200
#define MBED_CONF_SARA4_PPP_PROVIDE_DEFAULT 0
#define MBED_CONF_STM32_EMAC_ETH_PHY_ADDRESS 0
#define MBED_CONF_STM32_EMAC_ETH_PHY_AUTONEGOTIATION ETH_AUTONEGOTIATION_ENABLE
#define MBED_CONF_STM32_EMAC_ETH_PHY_DUPLEXMODE ETH_MODE_FULLDUPLEX
#define MBED_CONF_STM32_EMAC_ETH_PHY_DUPLEX_STATUS 0x0010
#define MBED_CONF_STM32_EMAC_ETH_PHY_MEDIA_INTERFACE ETH_MEDIA_INTERFACE_RMII
#define MBED_CONF_STM32_EMAC_ETH_PHY_RESET_DELAY 500
#define MBED_CONF_STM32_EMAC_ETH_PHY_SPEED ETH_SPEED_100M
#define MBED_CONF_STM32_EMAC_ETH_PHY_SPEED_STATUS 0x0004
#define MBED_CONF_STM32_EMAC_ETH_PHY_STATUS_REGISTER 31
#define MBED_CONF_STM32_EMAC_ETH_RXBUFNB 4
#define MBED_CONF_STM32_EMAC_ETH_TXBUFNB 10
#define MBED_CONF_STM32_EMAC_THREAD_STACKSIZE 1024
#define MBED_CONF_STORAGE_DEFAULT_KV kv
#define MBED_CONF_STORAGE_FILESYSTEM_BLOCKDEVICE default
#define MBED_CONF_STORAGE_FILESYSTEM_EXTERNAL_BASE_ADDRESS 0
#define MBED_CONF_STORAGE_FILESYSTEM_EXTERNAL_SIZE 0
#define MBED_CONF_STORAGE_FILESYSTEM_FILESYSTEM default
#define MBED_CONF_STORAGE_FILESYSTEM_FOLDER_PATH kvstore
#define MBED_CONF_STORAGE_FILESYSTEM_INTERNAL_BASE_ADDRESS 0
#define MBED_CONF_STORAGE_FILESYSTEM_MOUNT_POINT kv
#define MBED_CONF_STORAGE_FILESYSTEM_NO_RBP_BLOCKDEVICE default
#define MBED_CONF_STORAGE_FILESYSTEM_NO_RBP_EXTERNAL_BASE_ADDRESS 0
#define MBED_CONF_STORAGE_FILESYSTEM_NO_RBP_EXTERNAL_SIZE 0
#define MBED_CONF_STORAGE_FILESYSTEM_NO_RBP_FILESYSTEM default
#define MBED_CONF_STORAGE_FILESYSTEM_NO_RBP_FOLDER_PATH kvstore
#define MBED_CONF_STORAGE_FILESYSTEM_NO_RBP_MOUNT_POINT kv
#define MBED_CONF_STORAGE_FILESYSTEM_RBP_INTERNAL_SIZE 0
#define MBED_CONF_STORAGE_STORAGE_TYPE TDB_INTERNAL
#define MBED_CONF_STORAGE_TDB_EXTERNAL_BLOCKDEVICE default
#define MBED_CONF_STORAGE_TDB_EXTERNAL_EXTERNAL_BASE_ADDRESS 0
#define MBED_CONF_STORAGE_TDB_EXTERNAL_EXTERNAL_SIZE 0
#define MBED_CONF_STORAGE_TDB_EXTERNAL_INTERNAL_BASE_ADDRESS 0
#define MBED_CONF_STORAGE_TDB_EXTERNAL_NO_RBP_BLOCKDEVICE default
#define MBED_CONF_STORAGE_TDB_EXTERNAL_NO_RBP_EXTERNAL_BASE_ADDRESS 0
#define MBED_CONF_STORAGE_TDB_EXTERNAL_NO_RBP_EXTERNAL_SIZE 0
#define MBED_CONF_STORAGE_TDB_EXTERNAL_RBP_INTERNAL_SIZE 0
#define MBED_CONF_STORAGE_TDB_INTERNAL_INTERNAL_BASE_ADDRESS 0
#define MBED_CONF_STORAGE_TDB_INTERNAL_INTERNAL_SIZE 0
#define MBED_CONF_TARGET_BOOT_STACK_SIZE 0x400
#define MBED_CONF_TARGET_CONSOLE_UART 1
#define MBED_CONF_TARGET_CUSTOM_TICKERS 1
#define MBED_CONF_TARGET_DEEP_SLEEP_LATENCY 4
#define MBED_CONF_TARGET_DEFAULT_ADC_VREF NAN
#define MBED_CONF_TARGET_GPIO_RESET_AT_INIT 0
#define MBED_CONF_TARGET_I2C_TIMING_VALUE_ALGO 0
#define MBED_CONF_TARGET_INIT_US_TICKER_AT_BOOT 1
#define MBED_CONF_TARGET_INTERNAL_FLASH_UNIFORM_SECTORS 1
#define MBED_CONF_TARGET_LPTICKER_LPTIM 1
#define MBED_CONF_TARGET_LPTICKER_LPTIM_CLOCK 1
#define MBED_CONF_TARGET_LPUART_CLOCK_SOURCE USE_LPUART_CLK_LSE|USE_LPUART_CLK_PCLK1|USE_LPUART_CLK_PCLK3
#define MBED_CONF_TARGET_LSE_AVAILABLE 1
#define MBED_CONF_TARGET_LSE_DRIVE_LOAD_LEVEL RCC_LSEDRIVE_LOW
#define MBED_CONF_TARGET_MPU_ROM_END 0x0fffffff
#define MBED_CONF_TARGET_NETWORK_DEFAULT_INTERFACE_TYPE ETHERNET
#define MBED_CONF_TARGET_RTC_CLOCK_SOURCE USE_RTC_CLK_LSE_OR_LSI
#define MBED_CONF_TARGET_SYSTEM_POWER_SUPPLY PWR_LDO_SUPPLY
#define MBED_CONF_TARGET_TICKLESS_FROM_US_TICKER 0
#define MBED_CONF_TARGET_XIP_ENABLE 0
#define MBED_CONF_TELIT_HE910_BAUDRATE 115200
#define MBED_CONF_TELIT_HE910_PROVIDE_DEFAULT 0
#define MBED_CONF_TELIT_ME310_BAUDRATE 115200
#define MBED_CONF_TELIT_ME310_PROVIDE_DEFAULT 0
#define MBED_CONF_TELIT_ME910_BAUDRATE 115200
#define MBED_CONF_TELIT_ME910_PROVIDE_DEFAULT 0
#define MBED_CONF_UBLOX_AT_BAUDRATE 115200
#define MBED_CONF_UBLOX_AT_PROVIDE_DEFAULT 0
#define MBED_CONF_UBLOX_N2XX_BAUDRATE 9600
#define MBED_CONF_UBLOX_N2XX_PROVIDE_DEFAULT 0
#define MBED_CONF_UBLOX_PPP_BAUDRATE 115200
#define MBED_CONF_UBLOX_PPP_PROVIDE_DEFAULT 0
#define MBED_CRC_TABLE_SIZE 16
#define MBED_LFS2_BLOCK_CYCLES 1024
#define MBED_LFS2_BLOCK_SIZE 512
#define MBED_LFS2_CACHE_SIZE 64
#define MBED_LFS2_ENABLE_INFO 0
#define MBED_LFS2_INTRINSICS 1
#define MBED_LFS2_LOOKAHEAD_SIZE 64
#define MBED_LFS_BLOCK_SIZE 512
#define MBED_LFS_ENABLE_INFO 0
#define MBED_LFS_INTRINSICS 1
#define MBED_LFS_LOOKAHEAD 512
#define MBED_LFS_PROG_SIZE 64
#define MBED_LFS_READ_SIZE 64
#define MBED_STACK_DUMP_ENABLED 0
#define MBED_TRACE_COLOR_THEME 0
#define MEM_ALLOC malloc
#define MEM_FREE free
#define PPP_DEBUG 0
#define STM32_D11_SPI_ETHERNET_PIN PB_5
#define MBEDTLS_CIPHER_MODE_CTR 
#define NSAPI_PPP_AVAILABLE (MBED_CONF_PPP_ENABLED || MBED_CONF_LWIP_PPP_ENABLED)
#define NSDYNMEM_TRACKER_ENABLED MBED_CONF_NANOSTACK_LIBSERVICE_NSDYNMEM_TRACKER_ENABLED
#define NS_USE_EXTERNAL_MBED_TLS 
#define UNITY_INCLUDE_CONFIG_H 
#define _RTE_ 
#define MBED_CMSIS_NVIC_H 
#define NVIC_NUM_VECTORS 166
#define NVIC_RAM_VECTOR_ADDRESS MBED_RAM_START
#define MBED_APP_START MBED_ROM_START
#define MBED_APP_SIZE MBED_ROM_SIZE
M_CRASH_DATA_RAM_SIZE = 0x100;
#define VECTORS_SIZE (((NVIC_NUM_VECTORS * 4) + 7) & 0xFFFFFFF8)
MEMORY
{
  FLASH (rx) : ORIGIN = 0x8000000, LENGTH = 0x200000
  DTCMRAM (rwx) : ORIGIN = 0x20000000 + (((166 * 4) + 7) & 0xFFFFFFF8), LENGTH = 128K - (((166 * 4) + 7) & 0xFFFFFFF8)
  RAM (xrw) : ORIGIN = 0x24000000, LENGTH = 0x80000
  RAM_D2 (xrw) : ORIGIN = 0x30000000, LENGTH = 288K
  RAM_D3 (xrw) : ORIGIN = 0x38000000, LENGTH = 64K
  ITCMRAM (xrw) : ORIGIN = 0x00000000, LENGTH = 64K
}
ENTRY(Reset_Handler)
SECTIONS
{
    .text :
    {
        KEEP(*(.isr_vector))
        *(.text*)
        KEEP(*(.init))
        KEEP(*(.fini))
        *crtbegin.o(.ctors)
        *crtbegin?.o(.ctors)
        *(EXCLUDE_FILE(*crtend?.o *crtend.o) .ctors)
        *(SORT(.ctors.*))
        *(.ctors)
        *crtbegin.o(.dtors)
        *crtbegin?.o(.dtors)
        *(EXCLUDE_FILE(*crtend?.o *crtend.o) .dtors)
        *(SORT(.dtors.*))
        *(.dtors)
        *(.rodata*)
        KEEP(*(.eh_frame*))
    } > FLASH
    .ARM.extab :
    {
        *(.ARM.extab* .gnu.linkonce.armextab.*)
    } > FLASH
    __exidx_start = .;
    .ARM.exidx :
    {
        *(.ARM.exidx* .gnu.linkonce.armexidx.*)
    } > FLASH
    __exidx_end = .;
    __etext = .;
    _sidata = .;
    .crash_data_ram :
    {
        . = ALIGN(8);
        __CRASH_DATA_RAM__ = .;
        __CRASH_DATA_RAM_START__ = .;
        KEEP(*(.keep.crash_data_ram))
        *(.m_crash_data_ram)
        . += M_CRASH_DATA_RAM_SIZE;
        . = ALIGN(8);
        __CRASH_DATA_RAM_END__ = .;
    } > DTCMRAM
    .data : AT (__etext)
    {
        __data_start__ = .;
        _sdata = .;
        *(vtable)
        *(.data*)
        . = ALIGN(8);
        PROVIDE_HIDDEN (__preinit_array_start = .);
        KEEP(*(.preinit_array))
        PROVIDE_HIDDEN (__preinit_array_end = .);
        . = ALIGN(8);
        PROVIDE_HIDDEN (__init_array_start = .);
        KEEP(*(SORT(.init_array.*)))
        KEEP(*(.init_array))
        PROVIDE_HIDDEN (__init_array_end = .);
        . = ALIGN(8);
        PROVIDE_HIDDEN (__fini_array_start = .);
        KEEP(*(SORT(.fini_array.*)))
        KEEP(*(.fini_array))
        PROVIDE_HIDDEN (__fini_array_end = .);
        KEEP(*(.jcr*))
        . = ALIGN(8);
        __data_end__ = .;
        _edata = .;
    } > RAM
    .uninitialized (NOLOAD):
    {
        . = ALIGN(32);
        __uninitialized_start = .;
        *(.uninitialized)
        KEEP(*(.keep.uninitialized))
        . = ALIGN(32);
        __uninitialized_end = .;
    } > RAM
    .bss :
    {
        . = ALIGN(8);
        __bss_start__ = .;
        _sbss = .;
        *(.bss*)
        *(COMMON)
        . = ALIGN(8);
        __bss_end__ = .;
        _ebss = .;
    } > RAM
    .heap (COPY):
    {
        __end__ = .;
        PROVIDE(end = .);
        *(.heap*)
        . = ORIGIN(RAM) + LENGTH(RAM) - 0x400;
        __HeapLimit = .;
    } > RAM
    .stack_dummy (COPY):
    {
        *(.stack*)
    } > RAM
    __StackTop = ORIGIN(RAM) + LENGTH(RAM);
    _estack = __StackTop;
    __StackLimit = __StackTop - 0x400;
    PROVIDE(__stack = __StackTop);
    ASSERT(__StackLimit >= __HeapLimit, "region RAM overflowed with stack")
    .lwip_sec (NOLOAD) : {
        . = ABSOLUTE(0x30040000);
        *(.RxDecripSection)
        . = ABSOLUTE(0x30040100);
        *(.TxDecripSection)
        . = ABSOLUTE(0x30040400);
        *(.RxArraySection)
        . = ABSOLUTE(0x30044000);
        *(.ethusbram)
    } >RAM_D2 AT> FLASH
}
